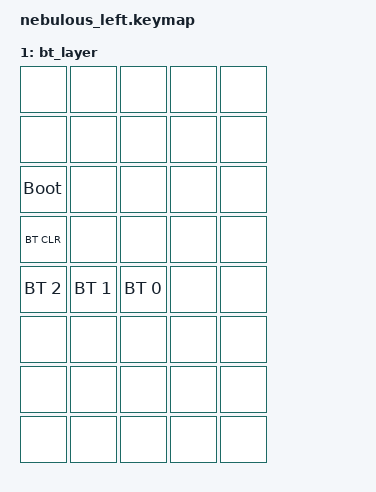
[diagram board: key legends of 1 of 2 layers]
#include <behaviors.dtsi>
#include <dt-bindings/zmk/keys.h>
#include <dt-bindings/zmk/bt.h>

/ {  
    keymap {
        compatible = "zmk,keymap";

        default_layer {
            bindings = <
                &kp N9  &kp N8  &kp N7  &bootloader
                &kp N0   &kp N1   &kp N2   &kp N3  &kp N4
                &kp RET &kp Q   &kp W   &kp E  &kp R
                &kp COLON   &kp A   &kp S   &kp D  &kp F
                &kp Z   &kp X   &kp C   &kp V  &kp B
                &kp N1   &kp SPACE
                &kp RET 
            >;
            
        };
                bt_layer {
            bindings = <
                &none 	&none   &none   &none 	&none
                &none 	&none   &none   &none 	&none
                &bootloader   &none   &none   &none   &none
                &bt BT_CLR   &none   &none   &none   &none
                &bt BT_SEL 2   &bt BT_SEL 1   &bt BT_SEL 0    &none     &none 
                &none 	&none   &none   &none 	&none
                &none 	&none   &none   &none 	&none
                &none 	&none   &none   &none 	&none
            >;
        };
    };
};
